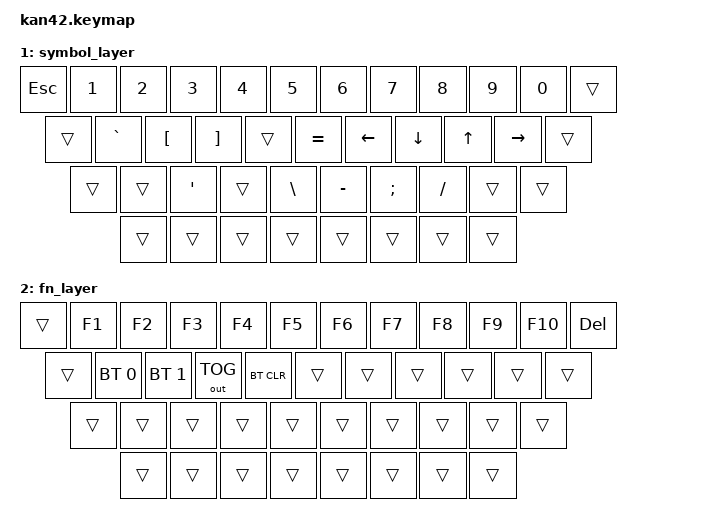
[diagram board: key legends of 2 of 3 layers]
#include <behaviors.dtsi>
#include <dt-bindings/zmk/bt.h>
#include <dt-bindings/zmk/outputs.h>

/ {
    keymap {
        compatible = "zmk,keymap";

        default_layer {
            bindings = <
&kp TAB    &kp Q     &kp W      &kp E      &kp R      &kp T        &kp Y     &kp U      &kp I      &kp O      &kp P     &kp BKSP
  &kp LCTL      &kp A       &kp S      &kp D      &kp F      &kp G        &kp H     &kp J      &kp K      &kp L      &kp ENTER
    &kp LSHFT       &kp Z     &kp X      &kp C      &kp V      &kp B        &kp N     &kp M      &kp COMMA  &kp DOT    &kp RSHFT
             &kp LALT   &kp LGUI &lt 1 LANG2   &kp SPACE              &mo 1   &lt 1 LANG1  &kp RGUI  &mo 2
>;
        };

        symbol_layer {
            bindings = <
&kp ESC    &kp N1     &kp N2     &kp N3     &kp N4     &kp N5       &kp N6    &kp N7     &kp N8     &kp N9     &kp N0    &trans
  &trans       &kp GRAVE    &kp LBKT  &kp RBKT        &trans     &kp EQUAL     &kp LEFT    &kp DOWN     &kp UP   &kp RIGHT      &trans
    &trans         &trans     &kp SQT   &trans     &kp BSLH    &kp MINUS     &kp SEMI    &kp FSLH    &trans    &trans
       &trans       &trans     &trans      &trans                &trans      &trans       &trans     &trans
>;
        };

        fn_layer {
            bindings = <
&trans   &kp F1   &kp F2   &kp F3   &kp F4   &kp F5    &kp F6   &kp F7   &kp F8   &kp F9   &kp F10   &kp DEL
  &trans   &bt BT_SEL 0  &bt BT_SEL 1  &out OUT_TOG  &bt BT_CLR  &trans    &trans   &trans   &trans   &trans   &trans
    &trans   &trans  &trans   &trans   &trans   &trans   &trans   &trans   &trans   &trans
       &trans   &trans  &trans   &trans             &trans   &trans  &trans   &trans
>;
        };
    };
};
